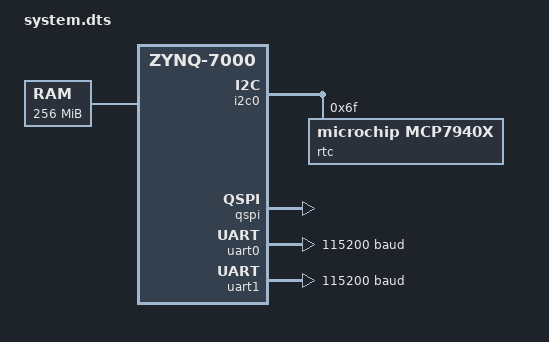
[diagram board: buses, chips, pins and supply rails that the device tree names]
/*
 * CAUTION: This file is automatically generated by Xilinx.
 * Version:  
 * Today is: Wed Apr 20 14:13:36 2016
*/


/dts-v1/;
/include/ "zynq-7000.dtsi"
/include/ "pl.dtsi"
/ {
	cpus {
		cpu@0 {
			operating-points = <666666 1000000 333333 1000000>;
		};
	};
	chosen {
		bootargs = "console=ttyPS0,115200 root=/dev/ram0 uio_pdrv_genirq.of_id=generic-uio isolcpus=1";
	};
	aliases {
		ethernet0 = &axi_ethernetlite_0;
		serial0 = &uart0;
		serial1 = &axi_uartlite_0;
		serial2 = &uart1;
		spi0 = &qspi;
	};
	memory {
		device_type = "memory";
		reg = <0x0 0x10000000>;
	};
	reserved_memory {
		device_type = "reserved_memory";
		reg = <0x10000000 0x1000 0x10001000 0xD0001000>;
		compatible = "generic-uio";
	};
};


&gpio0 {
	emio-gpio-width = <64>;
	gpio-mask-high = <0x0>;
	gpio-mask-low = <0x5600>;
};
&i2c0 {
	status = "okay";
	rtc@6F {
		compatible = "microchip,mcp7940x";
		reg = <0x6F>;
	};
	

};
&intc {
	num_cpus = <2>;
	num_interrupts = <96>;
};
&qspi {
	is-dual = <0>;
	num-cs = <1>;
	status = "okay";
};
&uart0 {
	current-speed = <115200>;
	device_type = "serial";
	port-number = <2>;
	status = "okay";
};
&uart1 {
	current-speed = <115200>;
	device_type = "serial";
	port-number = <3>;
	status = "okay";
};
&axi_ethernetlite_0 {
	local-mac-address = [00 0a 35 00 00 00];
};
&clkc {
	fclk-enable = <0x1>;
	ps-clk-frequency = <33333333>;
};
